# nrf7120E_enga_application register map
Vendor: Nordic Semiconductor; Series: nrf71; File version: 1
CPU: CM33 r0p4, little endian, MPU, FPU, 3 interrupt priority bits, 270 interrupts, 4 SAU regions
Registers are 32-bit, read-write, reset 0x0 unless marked. A register's access mark holds for its fields unless they carry their own. Offsets are from the block's base; [hi:lo] are bit positions; lines under a group give offsets from that group; {n}, {i} and the like mark numbered series.

## GLOBAL_USBHSCORE_NS (part 2 of 3) — USBHSCORE 0
Base 0x40020000
Same registers: GLOBAL_USBHSCORE_S 0x50020000
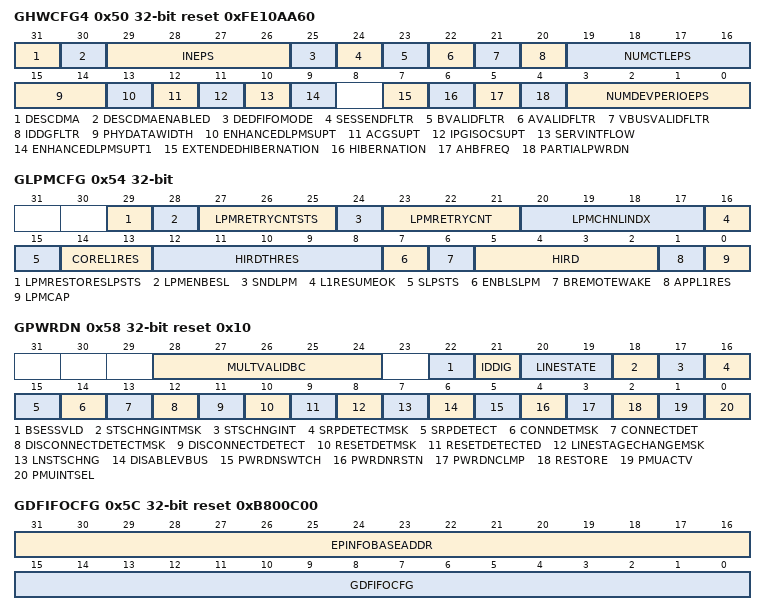
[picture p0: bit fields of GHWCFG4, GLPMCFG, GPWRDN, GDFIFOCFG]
0x50 GHWCFG4 reset 0xFE10AA60 — User Hardware Configuration 4 Register
  [31] DESCDMA ro — Scatter/Gather DMA configuration
    0=CONFIG1 (Non Dynamic configuration); 1=CONFIG2 (Dynamic configuration)
  [30] DESCDMAENABLED ro — Scatter/Gather DMA configuration
    0=DISABLE (Non-Scatter/Gather DMA configuration); 1=ENABLE (Scatter/Gather DMA configuration)
  [29:26] INEPS ro — Number of Device Mode IN Endpoints Including Control Endpoints (INEps)
    0=ENDPT1 (1 IN Endpoint); {v}=ENDPT{v+1} ({v+1} IN Endpoints) (v=1..15)
  [25] DEDFIFOMODE ro — Enable Dedicated Transmit FIFO for device IN Endpoints
    0=DISABLED (Dedicated Transmit FIFO Operation not enabled); 1=ENABLED (Dedicated Transmit FIFO Operation enabled)
  [24] SESSENDFLTR ro — session_end Filter Enabled (SessEndFltr)
    0=DISABLED (No filter); 1=ENABLED (Filter)
  [23] BVALIDFLTR ro — b_valid Filter Enabled (BValidFltr)
    0=DISABLED (No Filter); 1=ENABLED (Filter)
  [22] AVALIDFLTR ro — a_valid Filter Enabled (AValidFltr)
    0=DISABLED (No filter); 1=ENABLED (Filter)
  [21] VBUSVALIDFLTR ro — VBUS Valid Filter Enabled (VBusValidFltr)
    0=DISABLED (Vbus Valid Filter Disabled); 1=ENABLED (Vbus Valid Filter Enabled)
  [20] IDDGFLTR ro — IDDIG Filter Enable (IddgFltr)
    0=DISABLED (Iddig Filter Disabled); 1=ENABLED (Iddig Filter Enabled)
  [19:16] NUMCTLEPS ro — Number of Device Mode Control Endpoints in Addition to
    {v}=ENDPT{v} (End point {v}) (v=0..15)
  [15:14] PHYDATAWIDTH ro — UTMI+ PHY/ULPI-to-Internal UTMI+ Wrapper Data Width
    0=WIDTH1 (8 bits); 1=WIDTH2 (16 bits); 2=WIDTH3 (8/16 bits, software selectable)
  [13] ENHANCEDLPMSUPT ro — Enhanced LPM Support (EnhancedLPMSupt)
    1=ENABLED (Enhanced LPM Support is enabled)
  [12] ACGSUPT ro — Active Clock Gating Support
    0=DISABLED (Unspecified); 1=ENABLED (Active Clock Gating Support)
  [11] IPGISOCSUPT ro — Interpacket Gap ISOC OUT Worst-case Support (ipgisocSupt)
    0=DISABLED (Interpacket Gap ISOC OUT Worst-case Support is Disabled); 1=ENABLED (Interpacket Gap ISOC OUT Worst-case Support is Enabled (Default))
  [10] SERVINTFLOW ro — Service Interval Flow
    0=DISABLED (Service Interval Flow not supported); 1=ENABLED (Service Interval Flow supported)
  [9] ENHANCEDLPMSUPT1 ro — Enhanced LPM Support1 (EnhancedLPMSupt1)
    0=DISABLED (Reject L1 Request even if Non-Periodic (Bulk/Interrupt) TxFIFO is not empty.); 1=ENABLED (Accept L1 Request even if Non-Periodic (Bulk/Interrupt) TxFIFO is not empty)
  [7] EXTENDEDHIBERNATION ro — Enable Hibernation
    0=DISABLED (Extended Hibernation feature not enabled); 1=ENABLED (Extended Hibernation feature enabled)
  [6] HIBERNATION ro — Enable Hibernation (Hibernation)
    0=DISABLED (Hibernation feature disabled); 1=ENABLED (Hibernation feature enabled)
  [5] AHBFREQ ro — Minimum AHB Frequency Less Than 60 MHz (AhbFreq)
    0=DISABLED (Minimum AHB Frequency More Than 60 MHz); 1=ENABLED (Minimum AHB Frequency Less Than 60 MHz)
  [4] PARTIALPWRDN ro — Enable Partial Power Down (PartialPwrDn)
    0=DISABLED (Partial Power Down disabled); 1=ENABLED (Partial Power Down enabled)
  [3:0] NUMDEVPERIOEPS ro — Number of Device Mode Periodic IN Endpoints (NumDevPerioEps)
    {v}=Number of Periodic IN EPs is {v} (v=0..15)
0x54 GLPMCFG — LPM Config Register
  [29] LPMRESTORESLPSTS — LPM Restore Sleep Status (LPM_RestoreSlpSts)
    0=DISABLED (Puts the core in Shallow Sleep mode based on the BESL value from the Host); 1=ENABLED (Puts the core in Deep Sleep mode based on the BESL value from the Host)
  [28] LPMENBESL — LPM Enable BESL (LPM_EnBESL)
    0=DISABLED (BESL is disabled); 1=ENABLED (BESL is enabled as defined in LPM Errata)
  [27:25] LPMRETRYCNTSTS ro — LPM Retry Count Status (LPM_RetryCnt_Sts)
    0=RETRY_REM0 (Zero LPM retries remaining); 1=RETRY_REM1 (One LPM retry remaining); 2=RETRY_REM2 (Two LPM retries remaining); 3=RETRY_REM3 (Three LPM retries remaining); 4=RETRY_REM4 (Four LPM retries remaining); 5=RETRY_REM5 (Five LPM retries remaining); 6=RETRY_REM6 (Six LPM retries remaining); 7=RETRY_REM7 (Seven LPM retries remaining)
  [24] SNDLPM — Send LPM Transaction (SndLPM)
    0=DISABLED (In host-only mode: Received the response from the device for the LPM transaction); 1=ENABLED (In host-only mode: Sending LPM transaction containing EXT and LPM tokens)
  [23:21] LPMRETRYCNT — LPM Retry Count (LPM_Retry_Cnt)
    0=RETRY0 (Zero LPM retries); 1=RETRY1 (One LPM retry); 2=RETRY2 (Two LPM retries); 3=RETRY3 (Three LPM retries); 4=RETRY4 (Four LPM retries); 5=RETRY5 (Five LPM retries); 6=RETRY6 (Six LPM retries); 7=RETRY7 (Seven LPM retries)
  [20:17] LPMCHNLINDX — LPM Channel Index
    {v}=CH{v} (Channel {v}) (v=0..14); 15=CH15 (Channel15)
  [16] L1RESUMEOK ro — Sleep State Resume OK (L1ResumeOK)
    0=NOTOK (The application/core cannot start Resume from Sleep state); 1=OK (The application/core can start Resume from Sleep state)
  [15] SLPSTS ro — Port Sleep Status (SlpSts)
    0=CORE_NOT_IN_L1 (In Host or Device mode, this bit indicates core is not in L1); 1=CORE_IN_L1 (In Host mode, this bit indicates the core transitions to Sleep state as a successful LPM transaction. In Device mode, the core enters the Sleep state when an ACK response is sent to an LPM transaction)
  [14:13] COREL1RES ro — LPM Response (CoreL1Res)
    0=LPMRESP1 (ERROR : No handshake response); 1=LPMRESP2 (STALL response); 2=LPMRESP3 (NYET response); 3=LPMRESP4 (ACK response)
  [12:8] HIRDTHRES — BESL/HIRD Threshold (HIRD_Thres)
  [7] ENBLSLPM — Enable utmi_sleep_n (EnblSlpM)
    0=DISABLED (utmi_sleep_n assertion from the core is not transferred to the external PHY); 1=ENABLED (utmi_sleep_n assertion from the core is transferred to the external PHY when utmi_l1_suspend_n cannot be asserted)
  [6] BREMOTEWAKE — RemoteWakeEnable (bRemoteWake)
    0=DISABLED (Remote Wakeup is disabled); 1=ENABLED (In Host or device mode, this field takes the value of remote wake up)
  [5:2] HIRD — Host-Initiated Resume Duration (HIRD)
  [1] APPL1RES — Mode: Device only. LPM response programmed by application (AppL1Res)
    0=NYET_RESP (The core responds with a NYET when an error is detected in either of the LPM token packets due to corruption); 1=ACK_RESP (The core responds with an ACK only on a successful LPM transaction)
  [0] LPMCAP — LPM-Capable (LPMCap)
    0=DISABLED (LPM capability is not enabled); 1=ENABLED (LPM capability is enabled)
0x58 GPWRDN reset 0x10 — Global Power Down Register
  [28:24] MULTVALIDBC ro
    0=RID_0 (OTG device as B-device); 1=RID_C (OTG device as B-device, can connect); 2=RID_B (OTG device as B-device, cannot connect); 4=RID_A (OTG device as A-device); 8=RID_GND (ID_OTG pin is grounded); 12=RID_A_RID_GND (OTG device as A-device, RID_A=1 and RID_GND=1); 16=RID_FLOAT (ID pull down when ID_OTG is floating); 17=RID_C_RID_FLOAT (OTG device as B-device, can connect, RID_C=1 and RID_FLOAT=1); 18=RID_B_RID_FLOAT (OTG device as B-device, cannot connect, RID_B=1 and RID_FLOAT=1); 31=RID_1 (OTG device as A-device)
  [22] BSESSVLD ro — B Session Valid (BSessVld)
    0=NOTVALID (B_Valid is 0); 1=VALID (B_Valid is 1)
  [21] IDDIG ro — This bit indicates the status of the signal IDDIG. The application must read this bit after receiving GPWRDN.StsChngInt and decode based on the previous value stored by the application.
    0=DISABLED (Host Mode); 1=ENABLED (Device Mode)
  [20:19] LINESTATE ro
    0=LS1 (Linestate on USB: DM = 0, DP = 0); 1=LS2 (Linestate on USB: DM = 0, DP = 1); 2=LS3 (Linestate on USB: DM = 1, DP = 0); 3=LS4 (Linestate on USB: Not-defined)
  [18] STSCHNGINTMSK
    0=MASK (Mask for Status Change Interrupt); 1=NOMASK (No Status Change Interrupt Mask)
  [17] STSCHNGINT — Status Change Interrupt (StsChngInt)
    0=DISABLED (No Status change); 1=ENABLED (Status change detected)
  [16] SRPDETECTMSK
    0=NOMASK (No SRPDetect Interrupt Mask); 1=MASK (Mask for SRPDetect Interrupt)
  [15] SRPDETECT
    0=DISABLED (SRP not detected); 1=ENABLED (SRP detected)
  [14] CONNDETMSK
    0=NOMASK (No ConnectDet Interrupt Mask); 1=MASK (Mask for ConnectDet Interrupt)
  [13] CONNECTDET
    0=DISABLED (Connect not detected); 1=ENABLED (Connect detected)
  [12] DISCONNECTDETECTMSK
    0=MASK (Mask for DisconnectDetect Interrupt); 1=NOMASK (No DisconnectDetect Interrupt Mask)
  [11] DISCONNECTDETECT
    0=DISABLED (Disconnect not detected); 1=ENABLED (Disconnect detected)
  [10] RESETDETMSK
    0=MASK (Mask for ResetDetect Interrupt); 1=NOMASK (No ResetDetect Interrupt Mask)
  [9] RESETDETECTED
    0=DISABLED (Reset not detected); 1=ENABLED (Reset detected)
  [8] LINESTAGECHANGEMSK
    0=MASK (Mask for LineStateChange Interrupt); 1=NOMASK (No LineStateChange Interrupt Mask)
  [7] LNSTSCHNG — Line State Change (LnStsChng)
    0=DISABLED (No LineState change on USB); 1=ENABLED (LineState change on USB)
  [6] DISABLEVBUS
    0=DISABLED (Host mode:HPRT0.PrtPwr was not programmed to 0, and in Device mode:Session Valid); 1=ENABLED (Host mode:HPRT0.PrtPwr was programmed to 0 and in Device mode:Session End)
  [5] PWRDNSWTCH — Power Down Switch (PwrDnSwtch)
    0=ON (The controller is in ON state); 1=OFF (The controller is in OFF state)
  [4] PWRDNRSTN — Power Down ResetN (PwrDnRst_n)
    0=DISABLE (Reset the controller); 1=ENABLE (The controller is in normal operation)
  [3] PWRDNCLMP — Power Down Clamp (PwrDnClmp)
    0=DISABLE (Disable PMU power clamp); 1=ENABLE (Enable PMU power clamp)
  [2] RESTORE
    0=DISABLE (The controller in normal mode of operation); 1=ENABLE (The controller in Restore mode)
  [1] PMUACTV — PMU Active (PMUActv)
    0=DISABLE (Disable PMU module); 1=ENABLE (Enable PMU module)
  [0] PMUINTSEL — PMU Interrupt Select (PMUIntSel)
    0=DISABLE (Internal DWC_otg_core interrupt is selected); 1=ENABLE (External DWC_otg_pmu interrupt is selected)
0x5C GDFIFOCFG reset 0xB800C00 — Global DFIFO Configuration Register
  [31:16] EPINFOBASEADDR — This field provides the start address of the EP info controller.
  [15:0] GDFIFOCFG
0x68 GINTMSK2 — Interrupt Mask Register 2
0x6C GINTSTS2 — Interrupt Register 2
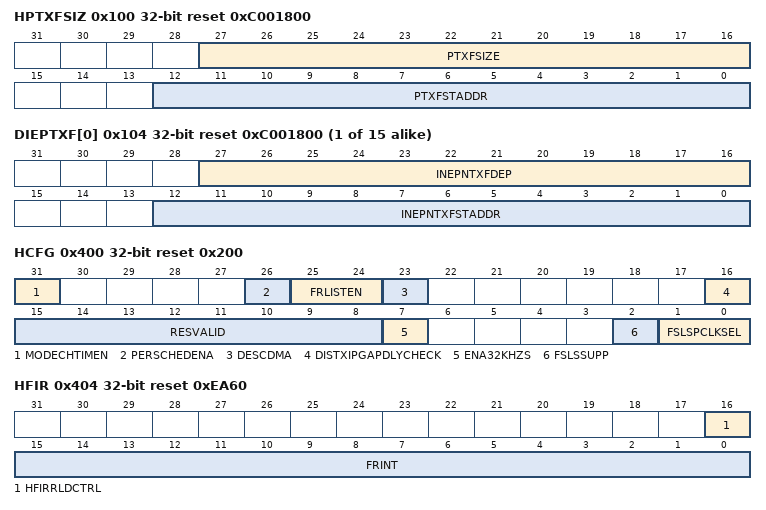
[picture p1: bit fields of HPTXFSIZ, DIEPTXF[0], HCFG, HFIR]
0x100 HPTXFSIZ reset 0xC001800 — Host Periodic Transmit FIFO Size Register
  [27:16] PTXFSIZE — Host Periodic TxFIFO Depth (PTxFSize)
  [12:0] PTXFSTADDR — Host Periodic TxFIFO Start Address (PTxFStAddr)
{0x104+4i} DIEPTXF[{i}] (i=0..14) reset 0xC001800 — Description collection: Device IN Endpoint Transmit FIFO 1 Size Register
  [27:16] INEPNTXFDEP — IN Endpoint TxFIFO Depth (INEPnTxFDep)
  [12:0] INEPNTXFSTADDR — IN Endpoint FIFOn Transmit RAM Start Address (INEPnTxFStAddr)
0x400 HCFG reset 0x200 — Host Configuration Register
  [31] MODECHTIMEN — Mode Change Ready Timer Enable (ModeChTimEn)
    0=ENABLED (The Host core waits for either 200 PHY clock cycles or a linestate of SE0 at the end of resume to change the opmode from 0x2 to 0x0); 1=DISABLED (The Host core waits only for a linestate of SE0 at the end of resume to change the opmode from 0x2 to 0x0)
  [26] PERSCHEDENA — Enable Periodic Scheduling (PerSchedEna):
    0=DISABLED (Disables periodic scheduling within the core); 1=ENABLED (Enables periodic scheduling within the core)
  [25:24] FRLISTEN — Frame List Entries(FrListEn)
    0=ENTRY8 (8 Entries); 1=ENTRY16 (16 Entries); 2=ENTRY32 (32 Entries); 3=ENTRY63 (64 Entries)
  [23] DESCDMA — Enable Scatter/gather DMA in Host mode (DescDMA)
    0=DISABLED (Scatter/Gather DMA in Host mode is disabled); 1=ENABLED (Scatter/Gather DMA selected)
  [16] DISTXIPGAPDLYCHECK — Disable Linestate check for Token to Token/Data interpacket gap delay calculation (dis_tx_ipgap_dly_check)
    0=DISABLE (Enable Linestate check); 1=ENABLE (Disable Linestate check)
  [15:8] RESVALID — Resume Validation Period (ResValid)
  [7] ENA32KHZS — Enable 32 KHz Suspend mode (Ena32KHzS)
    0=DISABLED (32 KHz Suspend mode disabled); 1=ENABLED (32 KHz Suspend mode enabled)
  [2] FSLSSUPP — FS- and LS-Only Support (FSLSSupp)
    0=HSFSLS (HS/FS/LS, based on the maximum speed supported by the connected device); 1=FSLS (FS/LS-only, even if the connected device can support HS)
  [1:0] FSLSPCLKSEL — FS/LS PHY Clock Select (FSLSPclkSel)
    0=CLK3060 (PHY clock is running at 30/60 MHz); 1=CLK48 (PHY clock is running at 48 MHz); 2=CLK6 (PHY clock is running at 6 MHz)
0x404 HFIR reset 0xEA60 — Host Frame Interval Register
  [16] HFIRRLDCTRL — Reload Control (HFIRRldCtrl)
    0=DISABLED (The HFIR cannot be reloaded dynamically); 1=ENABLED (The HFIR can be dynamically reloaded during runtime)
  [15:0] FRINT — Frame Interval (FrInt)
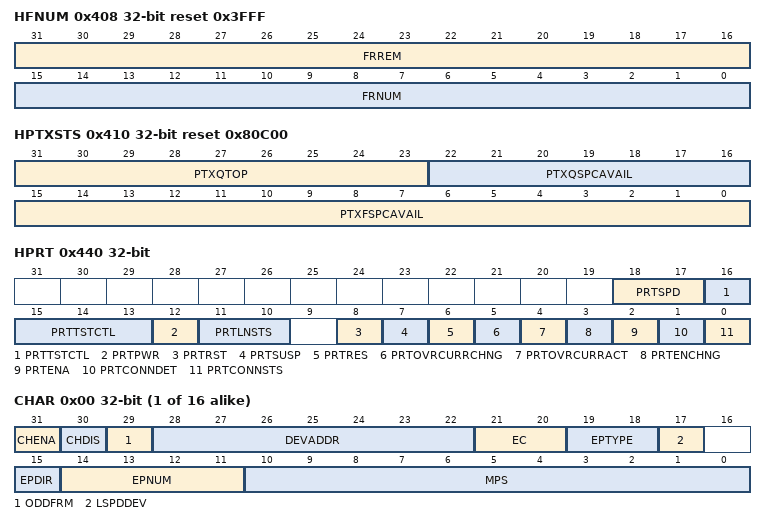
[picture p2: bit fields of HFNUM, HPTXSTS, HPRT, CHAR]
0x408 HFNUM reset 0x3FFF — Host Frame Number/Frame Time Remaining Register
  [31:16] FRREM ro — Frame Time Remaining (FrRem)
  [15:0] FRNUM ro — Frame Number (FrNum)
    0=INACTIVE (No SOF is transmitted); 1=ACTIVE (SOF is transmitted)
0x410 HPTXSTS reset 0x80C00 — Host Periodic Transmit FIFO/Queue Status Register
  [31:23] PTXQTOP ro — Top of the Periodic Transmit Request Queue (PTxQTop)
  [22:16] PTXQSPCAVAIL ro — Periodic Transmit Request Queue Space Available (PTxQSpcAvail)
    0=FULL (Periodic Transmit Request Queue is full); 1=FREE1 (1 location available); {v}=FREE{v} ({v} locations available) (v=2..15)
  [15:0] PTXFSPCAVAIL ro — Periodic Transmit Data FIFO Space Available (PTxFSpcAvail)
0x414 HAINT — Host All Channels Interrupt Register
  [15:0] HAINT ro
    0=INACTIVE (Not active); 1=ACTIVE (Host Channel Interrupt)
0x418 HAINTMSK — Host All Channels Interrupt Mask Register
  [15:0] HAINTMSK — Channel Interrupt Mask (HAINTMsk)
    0=MASK (Mask Channel interrupt); 1=UNMASK (UnMask Channel interrupt)
0x41C HFLBADDR — Host Frame List Base Address Register
  [31:0] HFLBADDR — The starting address of the Frame list.
0x440 HPRT — Host Port Control and Status Register
  [18:17] PRTSPD ro — Port Speed (PrtSpd)
    0=HIGHSPD (High speed); 1=FULLSPD (Full speed); 2=LOWSPD (Low speed)
  [16:13] PRTTSTCTL — Port Test Control (PrtTstCtl)
    0=DISABLED (Test mode disabled); 1=TESTJ (Test_J mode); 2=TESTK (Test_K mode); 3=TESTSN (Test_SE0_NAK mode); 4=TESTPM (Test_Packet mode); 5=TESTFENB (Test_force_Enable)
  [12] PRTPWR — Port Power (PrtPwr)
    0=OFF (Power off); 1=ON (Power on)
  [11:10] PRTLNSTS ro — Port Line Status (PrtLnSts)
    1=PLUSD (Logic level of D+); 2=MINUSD (Logic level of D-)
  [8] PRTRST — Port Reset (PrtRst)
    0=DISABLED (Port not in reset); 1=ENABLED (Port in reset)
  [7] PRTSUSP — Port Suspend (PrtSusp)
    0=INACTIVE (Port not in Suspend mode); 1=ACTIVE (Port in Suspend mode)
  [6] PRTRES — Port Resume (PrtRes)
    0=NORESUME (No resume driven); 1=RESUME (Resume driven)
  [5] PRTOVRCURRCHNG — Port Overcurrent Change (PrtOvrCurrChng)
    0=INACTIVE (Status of port overcurrent status is not changed); 1=ACTIVE (Status of port overcurrent changed)
  [4] PRTOVRCURRACT ro — Port Overcurrent Active (PrtOvrCurrAct)
    0=INACTIVE (No overcurrent condition); 1=ACTIVE (Overcurrent condition)
  [3] PRTENCHNG — Port Enable/Disable Change (PrtEnChng)
    0=INACTIVE (Port Enable bit 2 has not changed); 1=ACTIVE (Port Enable bit 2 changed)
  [2] PRTENA — Port Enable (PrtEna)
    0=DISABLED (Port disabled); 1=ENABLED (Port enabled)
  [1] PRTCONNDET — Port Connect Detected (PrtConnDet)
    0=INACTIVE (No device connection detected); 1=ACTIVE (Device connection detected)
  [0] PRTCONNSTS ro — Port Connect Status (PrtConnSts)
    0=NOTATTACHED (No device is attached to the port); 1=ATTACHED (A device is attached to the port)
{0x500+0x20*i} HC[{i}] (i=0..15) group — Unspecified
  0x00 CHAR — Description cluster: Host Channel Characteristics Register 0
    [31] CHENA — Channel Enable (ChEna)
      0=DISABLED (If Scatter/Gather mode is enabled, indicates that the descriptor structure is not yet ready. If Scatter/Gather mode is disabled, indicates that the channel is disabled.); 1=ENABLED (If Scatter/Gather mode is enabled, indicates that the descriptor structure and data buffer with data is set up and this channel can access the descriptor. If Scatter/Gather mode is disabled, indicates that the channel is enabled.)
    [30] CHDIS — Channel Disable (ChDis)
      0=INACTIVE (Transmit/Recieve normal); 1=ACTIVE (Stop transmitting/receiving data on channel)
    [29] ODDFRM — Odd Frame (OddFrm)
      0=EFRAME (Even Frame Transfer); 1=OFRAME (Odd Frame Transfer)
    [28:22] DEVADDR — Device Address (DevAddr)
    [21:20] EC — Multi Count (MC) / Error Count (EC)
      1=TRANSONE (1 transaction); 2=TRANSTWO (2 transactions to be issued for this endpoint per microframe); 3=TRANSTHREE (3 transactions to be issued for this endpoint per microframe)
    [19:18] EPTYPE — Endpoint Type (EPType)
      0=CTRL (Control); 1=ISOC (Isochronous); 2=BULK; 3=INTERR (Interrupt)
    [17] LSPDDEV — Low-Speed Device (LSpdDev)
      0=DISABLED (Not Communicating with low speed device); 1=ENABLED (Communicating with low speed device)
    [15] EPDIR — Endpoint Direction (EPDir)
      0=OUT (OUT Direction); 1=IN (IN Direction)
    [14:11] EPNUM — Endpoint Number (EPNum)
      {v}=ENDPT{v} (End point {v}) (v=0..15)
    [10:0] MPS — Maximum Packet Size (MPS)
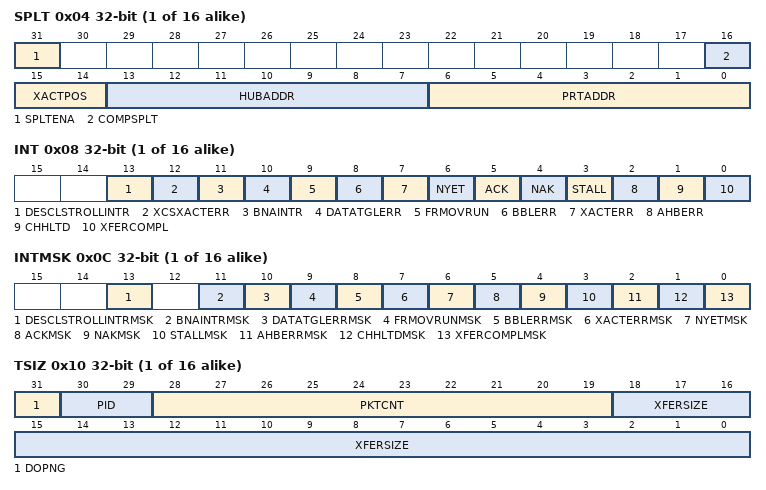
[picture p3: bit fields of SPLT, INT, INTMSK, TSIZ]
  0x04 SPLT — Description cluster: Host Channel Split Control Register 0
    [31] SPLTENA — Split Enable (SpltEna)
      0=DISABLED (Split not enabled); 1=ENABLED (Split enabled)
    [16] COMPSPLT — Do Complete Split (CompSplt)
      0=NOSPLIT (No complete split transaction); 1=SPLIT (Complete Split transaction)
    [15:14] XACTPOS — Transaction Position (XactPos)
      0=MIDDLE (Mid. This is the middle payload of this transaction (which is larger than 188 bytes)); 1=END (End. This is the last payload of this transaction (which is larger than 188 bytes)); 2=BEGIN (Begin. This is the first data payload of this transaction (which is larger than 188 bytes)); 3=ALL (All. This is the entire data payload of this transaction (which is less than or equal to 188 bytes))
    [13:7] HUBADDR — Hub Address (HubAddr)
    [6:0] PRTADDR — Port Address (PrtAddr)
  0x08 INT — Description cluster: Host Channel Interrupt Register 0
    [13] DESCLSTROLLINTR — Descriptor rollover interrupt (DESC_LST_ROLLIntr)
      0=INACTIVE (No Descriptor rollover interrupt); 1=ACTIVE (Descriptor rollover interrupt)
    [12] XCSXACTERR — Excessive Transaction Error (XCS_XACT_ERR)
      0=INACTIVE (No Excessive Transaction Error); 1=ACTIVE (Excessive Transaction Error)
    [11] BNAINTR — BNA (Buffer Not Available) Interrupt (BNAIntr)
      0=INACTIVE (No BNA Interrupt); 1=ACTIVE (BNA Interrupt)
    [10] DATATGLERR
      0=INACTIVE (No Data Toggle Error); 1=ACTIVE (Data Toggle Error)
    [9] FRMOVRUN — Frame Overrun (FrmOvrun).
      0=INACTIVE (No Frame Overrun); 1=ACTIVE (Frame Overrun)
    [8] BBLERR — Babble Error (BblErr)
      0=INACTIVE (No Babble Error); 1=ACTIVE (Babble Error)
    [7] XACTERR — Transaction Error (XactErr)
      0=INACTIVE (No Transaction Error); 1=ACTIVE (Transaction Error)
    [6] NYET — NYET Response Received Interrupt (NYET)
      0=INACTIVE (No NYET Response Received Interrupt); 1=ACTIVE (NYET Response Received Interrupt)
    [5] ACK — ACK Response Received/Transmitted Interrupt (ACK)
      0=INACTIVE (No ACK Response Received or Transmitted Interrupt); 1=ACTIVE (ACK Response Received or Transmitted Interrup)
    [4] NAK — NAK Response Received Interrupt (NAK)
      0=INACTIVE (No NAK Response Received Interrupt); 1=ACTIVE (NAK Response Received Interrupt)
    [3] STALL — STALL Response Received Interrupt (STALL)
      0=INACTIVE (No Stall Response Received Interrupt); 1=ACTIVE (Stall Response Received Interrupt)
    [2] AHBERR — AHB Error (AHBErr)
      0=INACTIVE (No AHB error); 1=ACTIVE (AHB error during AHB read/write)
    [1] CHHLTD — Channel Halted (ChHltd)
      0=INACTIVE (Channel not halted); 1=ACTIVE (Channel Halted)
    [0] XFERCOMPL — Transfer Completed (XferCompl)
      0=INACTIVE (Transfer in progress or No Active Transfer); 1=ACTIVE (Transfer completed normally without any errors)
  0x0C INTMSK — Description cluster: Host Channel Interrupt Mask Register 0
    [13] DESCLSTROLLINTRMSK
      0=MASK (Descriptor Rollover Interrupt Mask); 1=NOMASK (Descriptor Rollover Interrupt not masked)
    [11] BNAINTRMSK
      0=MASK (BNA Interrupt Masked); 1=NOMASK (BNA Interrupt not masked)
    [10] DATATGLERRMSK
      0=MASK (Mask Data Toggle Error); 1=NOMASK (No Data Toggle Error Mask)
    [9] FRMOVRUNMSK
      0=MASK (Mask Overrun Mask); 1=NOMASK (No Frame Overrun Mask)
    [8] BBLERRMSK
      0=MASK (Mask Babble Error); 1=NOMASK (No Babble Error Mask)
    [7] XACTERRMSK
      0=MASK (Mask Transaction Error); 1=NOMASK (No Transaction Error Mask)
    [6] NYETMSK
      0=MASK (Mask NYET Response Received Interrupt); 1=NOMASK (No NYET Response Received Interrupt Mask)
    [5] ACKMSK
      0=MASK (Mask ACK Response Received/Transmitted Interrupt); 1=NOMASK (No ACK Response Received/Transmitted Interrupt Mask)
    [4] NAKMSK
      0=MASK (Mask NAK Response Received Interrupt); 1=NOMASK (No NAK Response Received Interrupt Mask)
    [3] STALLMSK
      0=MASK (Mask STALL Response Received Interrupt); 1=NOMASK (No STALL Response Received Interrupt Mask)
    [2] AHBERRMSK
      0=MASK (AHB Error Mask); 1=NOMASK (No AHB Error Mask)
    [1] CHHLTDMSK
      0=MASK (Channel Halted Mask); 1=NOMASK (No Channel Halted Mask)
    [0] XFERCOMPLMSK
      0=MASK (Transfer Completed Mask); 1=NOMASK (No Transfer Completed Mask)
  0x10 TSIZ — Description cluster: Host Channel Transfer Size Register 0
    [31] DOPNG — Do Ping (DoPng)
      0=NOPING (No ping protocol); 1=PING (Ping protocol)
    [30:29] PID — PID (Pid)
      0=DATA0; 1=DATA2; 2=DATA1; 3=MDATA (MDATA (non-control)/SETUP (control))
    [28:19] PKTCNT — Non-Scatter/Gather DMA Mode:
    [18:0] XFERSIZE — Non-Scatter/Gather DMA Mode:
  0x14 DMA — Description cluster: Host Channel DMA Address Register 0
    [31:0] DMAADDR — In Buffer DMA Mode:
  0x1C DMAB — Description cluster: Host Channel DMA Buffer Address Register 0
    [31:0] HCDMAB ro — Holds the current buffer address.
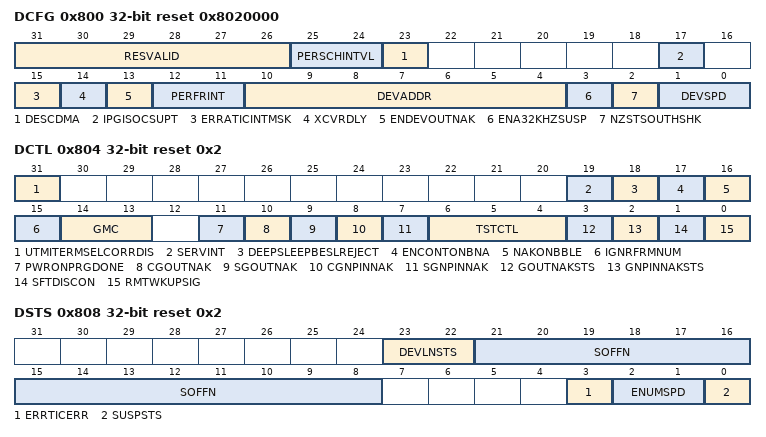
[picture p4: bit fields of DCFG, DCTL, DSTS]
0x800 DCFG reset 0x8020000 — Device Configuration Register
  [31:26] RESVALID — Resume Validation Period (ResValid)
  [25:24] PERSCHINTVL — Periodic Scheduling Interval (PerSchIntvl)
    0=MF25 (25 percent of (micro)Frame); 1=MF50 (50 percent of (micro)Frame); 2=MF75 (75 percent of (micro)Frame)
  [23] DESCDMA — Enable Scatter/gather DMA in device mode (DescDMA).
    0=DISABLED (Disable Scatter/Gather DMA); 1=ENABLED (Enable Scatter/Gather DMA)
  [17] IPGISOCSUPT — Worst-Case Inter-Packet Gap ISOC OUT Support (ipgisocSupt)
    0=DISABLED (Worst-Case Inter-Packet Gap ISOC OUT Support is disabled); 1=ENABLED (Worst-Case Inter-Packet Gap ISOC OUT Support is enabled)
  [15] ERRATICINTMSK — Erratic Error Interrupt Mask
    0=NOMASK (Early suspend interrupt is generated on erratic error); 1=MASK (Mask early suspend interrupt on erratic error)
  [14] XCVRDLY
    0=DISABLE (No delay between xcvr_sel and txvalid during Device chirp); 1=ENABLE (Enable delay between xcvr_sel and txvalid during Device chirp)
  [13] ENDEVOUTNAK — Enable Device OUT NAK (EnDevOutNak)
    0=DISABLED (The core does not set NAK after Bulk OUT transfer complete); 1=ENABLED (The core sets NAK after Bulk OUT transfer complete)
  [12:11] PERFRINT — Periodic Frame Interval (PerFrInt)
    0=EOPF80 (80 percent of the (micro)Frame interval); 1=EOPF85 (85 percent of the (micro)Frame interval); 2=EOPF90 (90 percent of the (micro)Frame interval); 3=EOPF95 (95 percent of the (micro)Frame interval)
  [10:4] DEVADDR — Device Address (DevAddr)
  [3] ENA32KHZSUSP — Enable 32 KHz Suspend mode (Ena32KHzSusp)
    0=DISABLED (USB 1.1 Full-Speed Serial Transceiver not selected); 1=ENABLED (USB 1.1 Full-Speed Serial Transceiver Interface selected)
  [2] NZSTSOUTHSHK — Non-Zero-Length Status OUT Handshake (NZStsOUTHShk)
    0=SENDOUT (Send the received OUT packet to the application (zero-length or non-zero length) and send a handshake based on NAK and STALL bits for the endpoint in the Devce Endpoint Control Register); 1=SENDSTALL (Send a STALL handshake on a nonzero-length status OUT transaction and do not send the received OUT packet to the application)
  [1:0] DEVSPD — Device Speed (DevSpd)
    0=USBHS20 (High speed USB 2.0 PHY clock is 30 MHz or 60 MHz); 1=USBFS20 (Full speed USB 2.0 PHY clock is 30 MHz or 60 MHz); 2=USBLS116 (Low speed USB 1.1 transceiver clock is 6 MHz); 3=USBFS1148 (Full speed USB 1.1 transceiver clock is 48 MHz)
0x804 DCTL reset 0x2 — Device Control Register
  [31] UTMITERMSELCORRDIS — Disable the correction of TermSel on UTMI Interface.
    0=DISABLED (Valid Combination of XcvrSel and TermSel is driven by the Device Controller.); 1=ENABLED (Invalid Combination of XcvrSel and TermSel is driven by the Device Controller.)
  [19] SERVINT — Service Interval based scheduling for Isochronous IN Endpoints
    0=DISABLED (The controller behavior depends on DCTL.IgnrFrmNum field.); 1=ENABLED (Scatter/Gather DMA Mode: The controller can transmit the packets in any frame of the service interval.)
  [18] DEEPSLEEPBESLREJECT
    0=DISABLED (Deep Sleep BESL Reject feature is disabled); 1=ENABLED (Deep Sleep BESL Reject feature is enabled)
  [17] ENCONTONBNA — Enable Continue on BNA (EnContOnBNA)
    0=DISABLED (Core disables the endpoint after receiving BNA interrupt. When application re-enables the endpoint, core starts processing from the DOEPDMA descriptor); 1=ENABLED (Core disables the endpoint after receiving BNA interrupt. When application re-enables the endpoint, core starts processing from the descriptor that received the BNA interrupt.)
  [16] NAKONBBLE — NAK on Babble Error (NakOnBble)
    0=DISABLED (Disable NAK on Babble Error); 1=ENABLED (NAK on Babble Error)
  [15] IGNRFRMNUM — Ignore Frame Number Feature for Isochronous Endpoints (IgnrFrmNum)
    0=DISABLED (Scatter/Gather DMA Mode: The core transmits the packets only in the frame number in which they are intended to be transmitted.Non-Scatter/Gather DMA Mode: Periodic Transfer Interrupt feature is disabled.); 1=ENABLED (Scatter/Gather DMA Mode: The core ignores the frame number, sending packets immediately as the packets are ready.Non-Scatter/Gather DMA Mode: Periodic Transfer Interrupt feature is enabled.)
  [14:13] GMC — Global Multi Count (GMC)
    0=NOTVALID (Invalid); 1=ONEPACKET (1 packet); 2=TWOPACKET (2 packets); 3=THREEPACKET (3 packets)
  [11] PWRONPRGDONE — Power-On Programming Done (PWROnPrgDone)
    0=NOTDONE (Power-On Programming not done); 1=DONE (Power-On Programming Done)
  [10] CGOUTNAK wo — Clear Global OUT NAK (CGOUTNak)
    0=DISABLED (Disable Clear Global OUT NAK); 1=ENABLED (Clear Global OUT NAK)
  [9] SGOUTNAK wo — Set Global OUT NAK (SGOUTNak)
    0=DISABLED (Disable Global OUT NAK); 1=ENABLED (Set Global OUT NAK)
  [8] CGNPINNAK wo — Clear Global Non-periodic IN NAK (CGNPInNak)
    0=DISABLE (Disable Global Non-periodic IN NAK); 1=ENABLE (Clear Global Non-periodic IN NAK)
  [7] SGNPINNAK wo — Set Global Non-periodic IN NAK (SGNPInNak)
    0=DISABLE (Disable Global Non-periodic IN NAK); 1=ENABLE (Set Global Non-periodic IN NAK)
  [6:4] TSTCTL — Test Control (TstCtl)
    0=DISABLED (Test mode disabled); 1=TESTJ (Test_J mode); 2=TESTK (Test_K mode); 3=TESTSN (Test_SE0_NAK mode); 4=TESTPM (Test_Packet mode); 5=TESTFE (Test_force_Enable)
  [3] GOUTNAKSTS ro — Global OUT NAK Status (GOUTNakSts)
    0=INACTIVE (A handshake is sent based on the FIFO Status and the NAK and STALL bit settings.); 1=ACTIVE (No data is written to the RxFIFO, irrespective of space availability. Sends a NAK handshake on all packets, except on SETUP transactions. All isochronous OUT packets are dropped.)
  [2] GNPINNAKSTS ro — Global Non-periodic IN NAK Status (GNPINNakSts)
    0=INACTIVE (A handshake is sent out based on the data availability in the transmit FIFO); 1=ACTIVE (A NAK handshake is sent out on all non-periodic IN endpoints, irrespective of the data availability in the transmit FIFO.)
  [1] SFTDISCON — Soft Disconnect (SftDiscon)
    0=NODISCONNECT (The core drives the phy_opmode_o signal on the UTMI+ to 2'b00, which generates a device connect event to the USB host); 1=DISCONNECT (The core drives the phy_opmode_o signal on the UTMI+ to 2'b01, which generates a device disconnect event to the USB host)
  [0] RMTWKUPSIG — Remote Wakeup Signaling (RmtWkUpSig)
    0=DISABLEDRMWKUP (Core does not send Remote Wakeup Signaling); 1=ENABLERMWKUP (Core sends Remote Wakeup Signaling)
0x808 DSTS reset 0x2 — Device Status Register
  [23:22] DEVLNSTS ro — Device Line Status (DevLnSts)
  [21:8] SOFFN ro — Frame or Microframe Number of the Received SOF (SOFFN)
  [3] ERRTICERR ro — Erratic Error (ErrticErr)
    0=INACTIVE (No Erratic Error); 1=ACTIVE (Erratic Error)
  [2:1] ENUMSPD ro — Enumerated Speed (EnumSpd)
    0=HS3060 (High speed (PHY clock is running at 30 or 60 MHz)); 1=FS3060 (Full speed (PHY clock is running at 30 or 60 MHz)); 2=LS6 (Low speed (PHY clock is running at 6 MHz)); 3=FS48 (Full speed (PHY clock is running at 48 MHz))
  [0] SUSPSTS ro — Suspend Status (SuspSts)
    0=INACTIVE (No suspend state); 1=ACTIVE (Suspend state)
